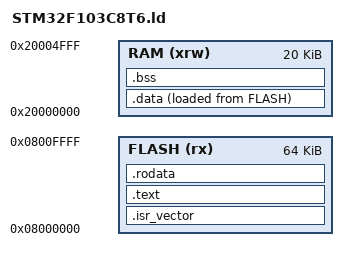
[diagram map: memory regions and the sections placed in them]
MEMORY
{
  FLASH (rx) : ORIGIN = 0x08000000, LENGTH = 64K
  RAM (xrw)  : ORIGIN = 0x20000000, LENGTH = 20K
}

SECTIONS
{
  .isr_vector :
  {
    . = ALIGN(4);
    KEEP(*(.isr_vector))
    . = ALIGN(4);
  } >FLASH

  .text :
  {
    . = ALIGN(4);
    *(.text*)
    *(.glue_7)
    *(.glue_7t)
    . = ALIGN(4);
  } >FLASH

  .rodata :
  {
    . = ALIGN(4);
    *(.rodata*)
    . = ALIGN(4);
  } >FLASH

  .data : 
  {
    . = ALIGN(4);
    _sdata = .;
    *(.data*)
    _edata = .;
  } >RAM AT> FLASH

  .bss :
  {
    . = ALIGN(4);
    _sbss = .;
    *(.bss*)
    *(COMMON)
    _ebss = .;
  } >RAM
}
